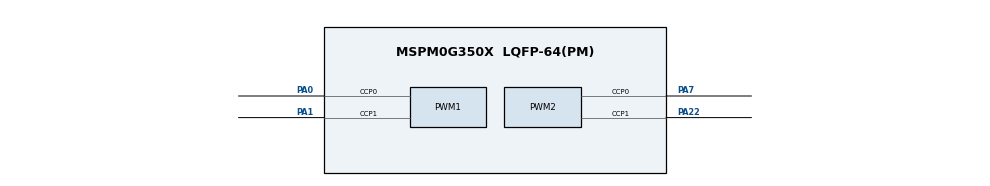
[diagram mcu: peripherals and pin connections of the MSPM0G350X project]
/**
 * @cliArgs --device "MSPM0G350X" --part "Default" --package "LQFP-64(PM)" --product "mspm0_sdk@2.04.00.06"
 * @versions {"tool":"1.23.0+4000"}
 */

/**
 * Import the modules used in this configuration.
 */
const GPIO   = scripting.addModule("/ti/driverlib/GPIO", {}, false);
const GPIO1  = GPIO.addInstance();
const GPIO2  = GPIO.addInstance();
const GPIO3  = GPIO.addInstance();
const GPIO4  = GPIO.addInstance();
const PWM    = scripting.addModule("/ti/driverlib/PWM", {}, false);
const PWM1   = PWM.addInstance();
const PWM2   = PWM.addInstance();
const SYSCTL = scripting.addModule("/ti/driverlib/SYSCTL");

/**
 * Write custom configuration values to the imported modules.
 */
const divider7       = system.clockTree["PLL_PDIV"];
divider7.divideValue = 2;

const divider9       = system.clockTree["UDIV"];
divider9.divideValue = 2;

const multiplier2         = system.clockTree["PLL_QDIV"];
multiplier2.multiplyValue = 5;

const mux8       = system.clockTree["HSCLKMUX"];
mux8.inputSelect = "HSCLKMUX_SYSPLL2X";

GPIO1.$name                              = "GPIO_Key1";
GPIO1.port                               = "PORTB";
GPIO1.associatedPins[0].direction        = "INPUT";
GPIO1.associatedPins[0].$name            = "PIN_Key1";
GPIO1.associatedPins[0].assignedPin      = "21";
GPIO1.associatedPins[0].internalResistor = "PULL_UP";

const Board = scripting.addModule("/ti/driverlib/Board", {}, false);

GPIO2.$name                          = "GPIO_OLED";
GPIO2.associatedPins.create(2);
GPIO2.associatedPins[0].$name        = "PIN_SCL";
GPIO2.associatedPins[0].initialValue = "SET";
GPIO2.associatedPins[0].assignedPort = "PORTA";
GPIO2.associatedPins[0].assignedPin  = "17";
GPIO2.associatedPins[1].$name        = "PIN_SDA";
GPIO2.associatedPins[1].initialValue = "SET";
GPIO2.associatedPins[1].assignedPort = "PORTB";
GPIO2.associatedPins[1].assignedPin  = "15";

GPIO3.$name                         = "GPIO_595";
GPIO3.port                          = "PORTA";
GPIO3.associatedPins.create(3);
GPIO3.associatedPins[0].assignedPin = "14";
GPIO3.associatedPins[0].$name       = "PIN_595STCP";
GPIO3.associatedPins[1].assignedPin = "15";
GPIO3.associatedPins[1].$name       = "PIN_595SHCP";
GPIO3.associatedPins[2].$name       = "PIN_595DS";
GPIO3.associatedPins[2].assignedPin = "25";

GPIO4.$name                               = "GPIO_Encoder";
GPIO4.port                                = "PORTB";
GPIO4.associatedPins.create(2);
GPIO4.associatedPins[0].$name             = "R2_E1";
GPIO4.associatedPins[0].direction         = "INPUT";
GPIO4.associatedPins[0].assignedPin       = "19";
GPIO4.associatedPins[0].interruptEn       = true;
GPIO4.associatedPins[0].interruptPriority = "0";
GPIO4.associatedPins[0].polarity          = "RISE";
GPIO4.associatedPins[1].$name             = "R2_E2";
GPIO4.associatedPins[1].direction         = "INPUT";
GPIO4.associatedPins[1].assignedPin       = "18";
GPIO4.associatedPins[1].interruptEn       = true;
GPIO4.associatedPins[1].interruptPriority = "0";
GPIO4.associatedPins[1].polarity          = "RISE";

PWM1.$name                              = "PWM_L";
PWM1.timerStartTimer                    = true;
PWM1.timerCount                         = 10000;
PWM1.clockDivider                       = 8;
PWM1.peripheral.$assign                 = "TIMA0";
PWM1.peripheral.ccp0Pin.$assign         = "PA0";
PWM1.peripheral.ccp1Pin.$assign         = "PA1";
PWM1.PWM_CHANNEL_0.$name                = "ti_driverlib_pwm_PWMTimerCC0";
PWM1.PWM_CHANNEL_0.ccValue              = 3999;
PWM1.PWM_CHANNEL_1.$name                = "ti_driverlib_pwm_PWMTimerCC1";
PWM1.PWM_CHANNEL_1.ccValue              = 3999;
PWM1.ccp0PinConfig.$name                = "ti_driverlib_gpio_GPIOPinGeneric0";
PWM1.ccp0PinConfig.direction            = scripting.forceWrite("OUTPUT");
PWM1.ccp0PinConfig.hideOutputInversion  = scripting.forceWrite(false);
PWM1.ccp0PinConfig.onlyInternalResistor = scripting.forceWrite(false);
PWM1.ccp0PinConfig.passedPeripheralType = scripting.forceWrite("Digital");
PWM1.ccp1PinConfig.$name                = "ti_driverlib_gpio_GPIOPinGeneric1";
PWM1.ccp1PinConfig.direction            = scripting.forceWrite("OUTPUT");
PWM1.ccp1PinConfig.hideOutputInversion  = scripting.forceWrite(false);
PWM1.ccp1PinConfig.onlyInternalResistor = scripting.forceWrite(false);
PWM1.ccp1PinConfig.passedPeripheralType = scripting.forceWrite("Digital");

PWM2.$name                              = "PWM_R";
PWM2.timerStartTimer                    = true;
PWM2.clockDivider                       = 4;
PWM2.timerCount                         = 10000;
PWM2.peripheral.$assign                 = "TIMG8";
PWM2.peripheral.ccp0Pin.$assign         = "PA7";
PWM2.peripheral.ccp1Pin.$assign         = "PA22";
PWM2.PWM_CHANNEL_0.$name                = "ti_driverlib_pwm_PWMTimerCC2";
PWM2.PWM_CHANNEL_0.ccValue              = 3999;
PWM2.PWM_CHANNEL_1.$name                = "ti_driverlib_pwm_PWMTimerCC3";
PWM2.PWM_CHANNEL_1.ccValue              = 3999;
PWM2.ccp0PinConfig.$name                = "ti_driverlib_gpio_GPIOPinGeneric2";
PWM2.ccp0PinConfig.direction            = scripting.forceWrite("OUTPUT");
PWM2.ccp0PinConfig.hideOutputInversion  = scripting.forceWrite(false);
PWM2.ccp0PinConfig.onlyInternalResistor = scripting.forceWrite(false);
PWM2.ccp0PinConfig.passedPeripheralType = scripting.forceWrite("Digital");
PWM2.ccp1PinConfig.$name                = "ti_driverlib_gpio_GPIOPinGeneric3";
PWM2.ccp1PinConfig.direction            = scripting.forceWrite("OUTPUT");
PWM2.ccp1PinConfig.hideOutputInversion  = scripting.forceWrite(false);
PWM2.ccp1PinConfig.onlyInternalResistor = scripting.forceWrite(false);
PWM2.ccp1PinConfig.passedPeripheralType = scripting.forceWrite("Digital");

SYSCTL.forceDefaultClkConfig = true;
SYSCTL.clockTreeEn           = true;
scripting.suppress("For best practices when the CPUCLK is running at 32MHz and above, clear the flash status bit using DL_FlashCTL_executeClearStatus\\(\\) before executing any flash operation\\. Otherwise there may be false positives\\.", SYSCTL);

/**
 * Pinmux solution for unlocked pins/peripherals. This ensures that minor changes to the automatic solver in a future
 * version of the tool will not impact the pinmux you originally saw.  These lines can be completely deleted in order to
 * re-solve from scratch.
 */
GPIO1.associatedPins[0].pin.$suggestSolution = "PB21";
Board.peripheral.$suggestSolution            = "DEBUGSS";
Board.peripheral.swclkPin.$suggestSolution   = "PA20";
Board.peripheral.swdioPin.$suggestSolution   = "PA19";
GPIO2.associatedPins[0].pin.$suggestSolution = "PA17";
GPIO2.associatedPins[1].pin.$suggestSolution = "PB15";
GPIO3.associatedPins[0].pin.$suggestSolution = "PA14";
GPIO3.associatedPins[1].pin.$suggestSolution = "PA15";
GPIO3.associatedPins[2].pin.$suggestSolution = "PA25";
GPIO4.associatedPins[0].pin.$suggestSolution = "PB19";
GPIO4.associatedPins[1].pin.$suggestSolution = "PB18";
